# PIC32MK1024MCF064 device description
Architecture: MIPS; Family: PIC32MK; Series: PIC32MK
Registers are 32-bit, read-write, no defined reset value unless marked. A register's access mark holds for its fields unless they carry their own. Offsets are from the block's base; [hi:lo] are bit positions; 'fields as' and 'values as' point back to an identical list.

## TMR1
Instances: TMR1 0x1f820000 in periph_pb2_std
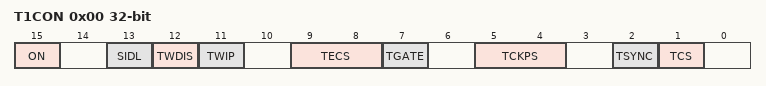
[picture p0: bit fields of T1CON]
0x00 T1CON — TYPE A TIMER CONTROL REGISTER
  [15] ON — Timer On bit
    1=Timer is enabled; 0=Timer is disabled
  [13] SIDL — Stop in Idle Mode bit
    1=Discontinue operation when device enters Idle mode; 0=CONTINUE (Continue operation even in Idle mode)
  [12] TWDIS — Asynchronous Timer Write Disable bit
    1=Writes to TMR1 are ignored until pending write operation completes; 0=Back-to-back writes are enabled (Legacy Asynchronous Timer functionality)
  [11] TWIP — Asynchronous Timer Write in Progress bit
    1=(In Asynchronous Timer mode) Asynchronous write to TMR1 register in progress / (In Synchronous Timer mode)bit is read as 0; 0=In Asynchronous Timer mode Asynchronous write to TMR1 register complete / (In Synchronous Timer mode)bit is read as 0
  [9:8] TECS — Timer1 External Clock Selection bits
    2=External clock comes from the LPRC; 1=External clock comes from the T1CK pin; 0=External clock comes from the SOSC
  [7] TGATE — Timer Gated Time Accumulation Enable bit
    1=(When TCS is 0) Gated time accumulation is enabled / (When TCS is 1) bit is ignored; 0=(When TCS is 0) Gated time accumulation is disabled / (When TCS is 1) bit is ignored
  [5:4] TCKPS — Timer Input Clock Prescale Select bits
    3=1:256 prescale value; 2=1:64 prescale value; 1=1:8 prescale value; 0=1:1 prescale value
  [2] TSYNC — Timer External Clock Input Synchronization Selection bit
    1=(When TCS is 1) External clock input is synchronized / (When TCS is 0) This bit is ignored; 0=(When TCS is 1) External clock input is not synchronized / (When TCS is 0) This bit is ignored
  [1] TCS — Timer Clock Source Select bit
    1=External clock is defined by the TECS bits; 0=INT_CLK (Internal peripheral clock)
0x10 TMR1
0x20 PR1

## TMR
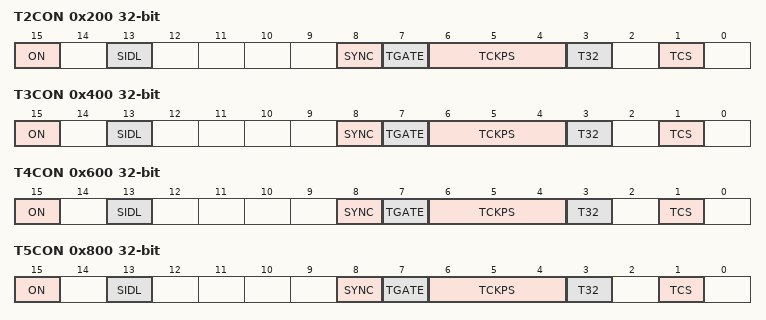
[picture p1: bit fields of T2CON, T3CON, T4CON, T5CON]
0x200 T2CON — Timer Configuration
  [15] ON — Timer On bit
    1=ON (Module is enabled); 0=OFF (Module is disabled)
  [13] SIDL — Stop in Idle Mode bit
    1=STOP (Discontinue operation when device enters Idle mode); 0=CONTINUE (Continue operation even in Idle mode)
  [8] SYNC — Synchronized Timer Start/Stop Enable bit
    1=ENABLED (Synchronized timer Start/Stop is enabled); 0=DISABLED (Synchronized timer Start/Stop is disabled)
  [7] TGATE — Timer Gated Time Accumulation Enable bit
    1=ENABLED (Gated time accumulation is enabled); 0=DISABLED (Gated time accumulation is disabled)
  [6:4] TCKPS — Timer Input Clock Prescale Select bits
    7=DIV_256 (1:256 prescale value); 6=DIV_64 (1:64 prescale value); 5=DIV_32 (1:32 prescale value); 4=DIV_16 (1:16 prescale value); 3=DIV_8 (1:8 prescale value); 2=DIV_4 (1:4 prescale value); 1=DIV_2 (1:2 prescale value); 0=DIV_1 (1:1 prescale value)
  [3] T32 — 32-Bit Timer Mode Select bit
    1=32_BIT (32-bit Timer mode); 0=16_BIT (16-bit Timer mode)
  [1] TCS — Timer Clock Source Select bit
    1=EXT_CLK (External clock from TxCK pin); 0=INT_CLK (Internal peripheral clock)
0x210 TMR2 — Timer
0x220 PR2 — Timer Period
0x400 T3CON — Timer Configuration
  fields as T2CON
0x410 TMR3 — Timer
0x420 PR3 — Timer Period
0x600 T4CON — Timer Configuration
  fields as T2CON
0x610 TMR4 — Timer
0x620 PR4 — Timer Period
0x800 T5CON — Timer Configuration
  fields as T2CON
0x810 TMR5 — Timer
0x820 PR5 — Timer Period
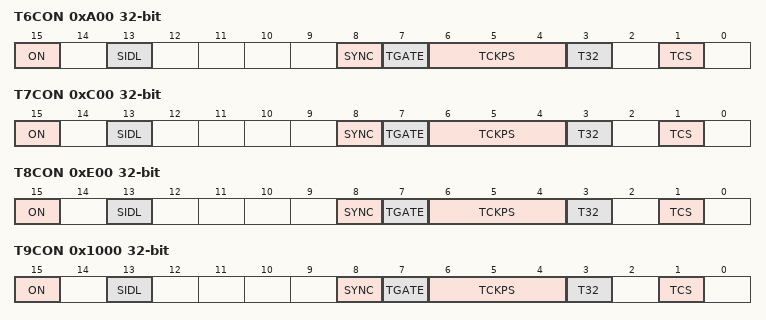
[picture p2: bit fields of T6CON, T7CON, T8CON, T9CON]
0xA00 T6CON — Timer Configuration
  fields as T2CON
0xA10 TMR6 — Timer
0xA20 PR6 — Timer Period
0xC00 T7CON — Timer Configuration
  fields as T2CON
0xC10 TMR7 — Timer
0xC20 PR7 — Timer Period
0xE00 T8CON — Timer Configuration
  fields as T2CON
0xE10 TMR8 — Timer
0xE20 PR8 — Timer Period
0x1000 T9CON — Timer Configuration
  fields as T2CON
0x1010 TMR9 — Timer
0x1020 PR9 — Timer Period

## WDT
Instances: WDT 0x1f800c00 in periph_pb1_std
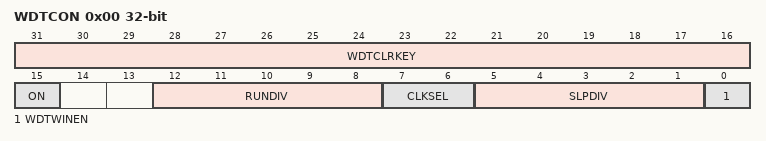
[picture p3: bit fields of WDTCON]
0x00 WDTCON — Watchdog Timer Control Register
  [31:16] WDTCLRKEY
  [15] ON — Watchdog Timer Enable bit
    1=The WDT is enabled; 0=The WDT is disabled
  [12:8] RUNDIV
  [7:6] CLKSEL
  [5:1] SLPDIV
  [0] WDTWINEN — Watchdog Timer Window Enable bit
    1=Enable windowed Watchdog Timer; 0=Disable windowed Watchdog Timer
